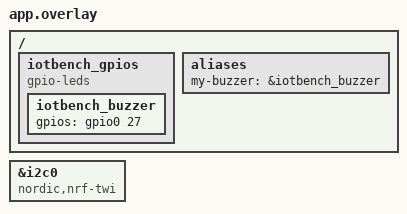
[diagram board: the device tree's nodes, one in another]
&i2c0 {
	compatible = "nordic,nrf-twi";
};

/ {
	iotbench_gpios {
		compatible = "gpio-leds";
		iotbench_buzzer: iotbench_buzzer {
			gpios = <&gpio0 27 GPIO_ACTIVE_HIGH>;
		};
	};
	aliases {
		my-buzzer = &iotbench_buzzer;
	};
};
